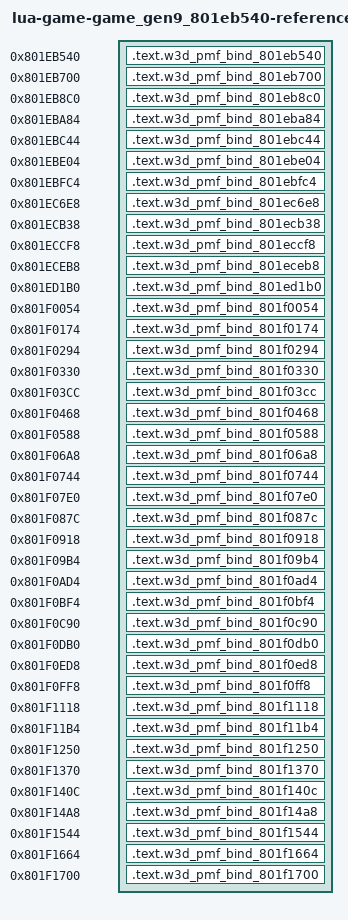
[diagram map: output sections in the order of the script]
/* Generated reference-only placements. All bodies are source-built. */
OUTPUT_FORMAT("elf32-powerpc")
OUTPUT_ARCH(powerpc)
ENTRY(w3d_pmf_bind_801eb540)
_SDA_BASE_ = 0x804b2540;
_SDA2_BASE_ = 0x804c2540;
SECTIONS {
  .text.w3d_pmf_bind_801eb540 0x801eb540 : { *(.text.w3d_pmf_bind_801eb540) }
  .text.w3d_pmf_bind_801eb700 0x801eb700 : { *(.text.w3d_pmf_bind_801eb700) }
  .text.w3d_pmf_bind_801eb8c0 0x801eb8c0 : { *(.text.w3d_pmf_bind_801eb8c0) }
  .text.w3d_pmf_bind_801eba84 0x801eba84 : { *(.text.w3d_pmf_bind_801eba84) }
  .text.w3d_pmf_bind_801ebc44 0x801ebc44 : { *(.text.w3d_pmf_bind_801ebc44) }
  .text.w3d_pmf_bind_801ebe04 0x801ebe04 : { *(.text.w3d_pmf_bind_801ebe04) }
  .text.w3d_pmf_bind_801ebfc4 0x801ebfc4 : { *(.text.w3d_pmf_bind_801ebfc4) }
  .text.w3d_pmf_bind_801ec6e8 0x801ec6e8 : { *(.text.w3d_pmf_bind_801ec6e8) }
  .text.w3d_pmf_bind_801ecb38 0x801ecb38 : { *(.text.w3d_pmf_bind_801ecb38) }
  .text.w3d_pmf_bind_801eccf8 0x801eccf8 : { *(.text.w3d_pmf_bind_801eccf8) }
  .text.w3d_pmf_bind_801eceb8 0x801eceb8 : { *(.text.w3d_pmf_bind_801eceb8) }
  .text.w3d_pmf_bind_801ed1b0 0x801ed1b0 : { *(.text.w3d_pmf_bind_801ed1b0) }
  .text.w3d_pmf_bind_801f0054 0x801f0054 : { *(.text.w3d_pmf_bind_801f0054) }
  .text.w3d_pmf_bind_801f0174 0x801f0174 : { *(.text.w3d_pmf_bind_801f0174) }
  .text.w3d_pmf_bind_801f0294 0x801f0294 : { *(.text.w3d_pmf_bind_801f0294) }
  .text.w3d_pmf_bind_801f0330 0x801f0330 : { *(.text.w3d_pmf_bind_801f0330) }
  .text.w3d_pmf_bind_801f03cc 0x801f03cc : { *(.text.w3d_pmf_bind_801f03cc) }
  .text.w3d_pmf_bind_801f0468 0x801f0468 : { *(.text.w3d_pmf_bind_801f0468) }
  .text.w3d_pmf_bind_801f0588 0x801f0588 : { *(.text.w3d_pmf_bind_801f0588) }
  .text.w3d_pmf_bind_801f06a8 0x801f06a8 : { *(.text.w3d_pmf_bind_801f06a8) }
  .text.w3d_pmf_bind_801f0744 0x801f0744 : { *(.text.w3d_pmf_bind_801f0744) }
  .text.w3d_pmf_bind_801f07e0 0x801f07e0 : { *(.text.w3d_pmf_bind_801f07e0) }
  .text.w3d_pmf_bind_801f087c 0x801f087c : { *(.text.w3d_pmf_bind_801f087c) }
  .text.w3d_pmf_bind_801f0918 0x801f0918 : { *(.text.w3d_pmf_bind_801f0918) }
  .text.w3d_pmf_bind_801f09b4 0x801f09b4 : { *(.text.w3d_pmf_bind_801f09b4) }
  .text.w3d_pmf_bind_801f0ad4 0x801f0ad4 : { *(.text.w3d_pmf_bind_801f0ad4) }
  .text.w3d_pmf_bind_801f0bf4 0x801f0bf4 : { *(.text.w3d_pmf_bind_801f0bf4) }
  .text.w3d_pmf_bind_801f0c90 0x801f0c90 : { *(.text.w3d_pmf_bind_801f0c90) }
  .text.w3d_pmf_bind_801f0db0 0x801f0db0 : { *(.text.w3d_pmf_bind_801f0db0) }
  .text.w3d_pmf_bind_801f0ed8 0x801f0ed8 : { *(.text.w3d_pmf_bind_801f0ed8) }
  .text.w3d_pmf_bind_801f0ff8 0x801f0ff8 : { *(.text.w3d_pmf_bind_801f0ff8) }
  .text.w3d_pmf_bind_801f1118 0x801f1118 : { *(.text.w3d_pmf_bind_801f1118) }
  .text.w3d_pmf_bind_801f11b4 0x801f11b4 : { *(.text.w3d_pmf_bind_801f11b4) }
  .text.w3d_pmf_bind_801f1250 0x801f1250 : { *(.text.w3d_pmf_bind_801f1250) }
  .text.w3d_pmf_bind_801f1370 0x801f1370 : { *(.text.w3d_pmf_bind_801f1370) }
  .text.w3d_pmf_bind_801f140c 0x801f140c : { *(.text.w3d_pmf_bind_801f140c) }
  .text.w3d_pmf_bind_801f14a8 0x801f14a8 : { *(.text.w3d_pmf_bind_801f14a8) }
  .text.w3d_pmf_bind_801f1544 0x801f1544 : { *(.text.w3d_pmf_bind_801f1544) }
  .text.w3d_pmf_bind_801f1664 0x801f1664 : { *(.text.w3d_pmf_bind_801f1664) }
  .text.w3d_pmf_bind_801f1700 0x801f1700 : { *(.text.w3d_pmf_bind_801f1700) }
  /DISCARD/ : { *(.text*) *(.rodata*) *(.data*) *(.bss*) *(.sdata*) *(.sbss*) *(.comment) }
}
